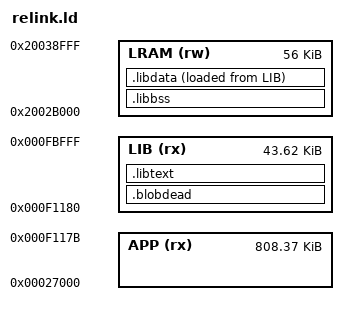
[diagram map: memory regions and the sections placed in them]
/* Link the app blob (abi/blobify.py) against a FreeRTOS built from source.
 *
 * The blob stays at its original 0x27000; the source kernel goes into the free
 * flash argued for in facts.yaml's LIBRARY_FLASH, which starts at the app image
 * end so app and library are one contiguous block, and its statics into
 * LIBRARY_RAM. The blob's own copy of the kernel stays in place and becomes
 * dead: the relocations point every app call at LIB instead. */

MEMORY
{
    APP   (rx)  : ORIGIN = 0x00027000, LENGTH = 0x000ca17c
    /* Immediately after the app image (0xf117c) so that `appl` stays one part:
     * a package describes each part by one address and one length, and the
     * bootloader copies that many bytes to 0x27000 in one go. The four bytes of
     * padding are the section's own alignment -- relink_glue.c's naked
     * vPortEnableVFP ends in `.align 4`, so .libtext wants 16 -- and
     * relink_image.py takes the placed address out of the ELF rather than
     * trusting this number. */
    LIB   (rx)  : ORIGIN = 0x000f1180, LENGTH = 0x0000ae80
    /* facts.yaml's LIBRARY_RAM: room for the source heap_4's ucHeap, which is
     * 35000 bytes because that is what the image's is. It starts 0x200 above
     * the highest static a 600 s run wrote and ends 0x6000 below the deepest
     * the main stack reached in the same run. */
    LRAM  (rw)  : ORIGIN = 0x2002b000, LENGTH = 0x0000e000
}

ENTRY(Reset_Handler)

/* port.c reads the initial MSP out of the app's vector table. */
PROVIDE(__isr_vector = appl_vector_table);

SECTIONS
{
    /* One placement per section, generated by abi/blobify.py from the
     * partition: in this step every section keeps its original address, so the
     * app's bytes are unchanged and only the library moves. */
    INCLUDE relink-place.ld

    /* --layout pack leaves out of the placement every section the link is
     * about to drop -- a body abi/replacements.yaml replaced, which is
     * undefined in the object and referenced by nothing, and a section neither
     * the object nor the KEEP list reaches -- and counts their bytes as free
     * flash for the library. This catches one that survives after all: it is
     * linked and relocated correctly, it costs the library region instead of
     * overlapping what was packed over it, and `size -A` names it. Under every
     * other layout the fragment names every section and this stays empty. */
    .blobdead : ALIGN(4)
    {
        *appl-blob.o(.text.* .rodata.*)
        *appl-data.o(.text.* .rodata.*)
        . = ALIGN(4);
    } > LIB

    .libtext : ALIGN(4)
    {
        *(.text .text.*)
        *(.rodata .rodata.*)
        . = ALIGN(4);
    } > LIB

    .libbss (NOLOAD) : ALIGN(4)
    {
        __libbss_start = .;
        *(.bss .bss.* COMMON)
        . = ALIGN(4);
        __libbss_end = .;
    } > LRAM

    /* The blob's Reset_Handler copies the blob's own .data and knows nothing
     * about this one, so relink_startup (relink_glue.c) copies it from the
     * load image the linker leaves in LIB. newlib is what makes it non-empty:
     * `impure_data` is an initialised struct _reent and `_impure_ptr` points at
     * it, and both the app and the library read that pointer. */
    .libdata : ALIGN(4)
    {
        __libdata_start = .;
        *(.data .data.*)
        . = ALIGN(4);
        __libdata_end = .;
    } > LRAM AT> LIB
    __libdata_load = LOADADDR(.libdata);

    /* A body abi/replacements.yaml replaced is undefined in the object and
     * every reference into it binds to the source's symbol, so nothing links it
     * in. --layout pack counts those bytes as free and packs the rest of the
     * text over them, which means leaving them out of the placement fragment;
     * this is where one lands if that is ever wrong, and the library region
     * overflowing is how the link says so. Under every other layout the
     * fragment names them first and they stay where they were. */
    /DISCARD/ : { *(.ARM.exidx*) *(.comment) *(.note*) *(.debug*) }
}

/* configTASK_RETURN_ADDRESS. The LR pxPortInitialiseStack puts under a new task
 * is 0x97f25 in the image, and 0x97f24 is a bare `udf #0`: a task that returns
 * traps. The address belongs to no named body -- it is one instruction that
 * nothing calls -- so the port binds to it here rather than through a name. */
PROVIDE(vTaskReturnTrap = 0x97f25);

/* The blob reaches __stdio_exit_handler as __sf + 0x138 -- it is the word after
 * the three FILEs, in the same translation unit -- and abi/replacements.yaml's
 * newlib group relocates only __sf, so the two have to stay that far apart. The
 * PROVIDEs are what makes the link without newlib pass the same assertion:
 * neither symbol exists there, and a link that defines one defines both. */
PROVIDE(__sf = 0);
PROVIDE(__stdio_exit_handler = 0x138);
ASSERT(__stdio_exit_handler - __sf == 0x138,
       "newlib's __stdio_exit_handler is no longer the word after __sf[3]")
